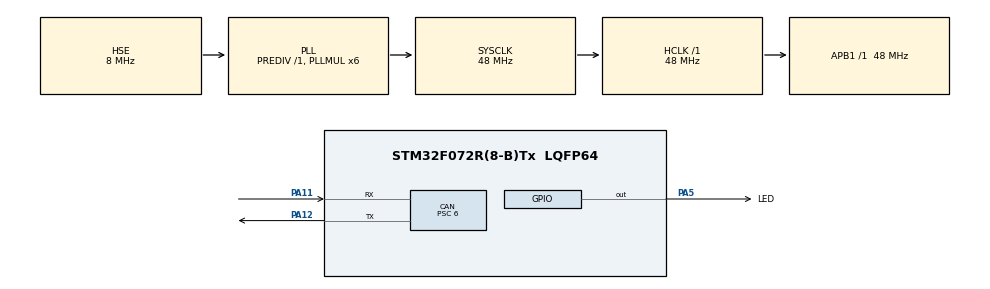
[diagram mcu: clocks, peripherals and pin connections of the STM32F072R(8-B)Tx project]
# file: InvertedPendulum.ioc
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CAN.ABOM=ENABLE
CAN.BS1=CAN_BS1_6TQ
CAN.CalculateBaudRate=1000000
CAN.CalculateTimeBit=1000
CAN.CalculateTimeQuantum=125.0
CAN.NART=DISABLE
CAN.Prescaler=6
Mcu.Family=STM32F0
Mcu.Name=STM32F072R(8-B)Tx
Mcu.Package=LQFP64
NVIC.CEC_CAN_IRQn=true\:0\:0\:false\:false\:true\:true\:true\:true
PA11.Mode=CAN_Activate
PA11.Signal=CAN_RX
PA12.Mode=CAN_Activate
PA12.Signal=CAN_TX
PA5.GPIO_Label=LED
PA5.Signal=GPIO_Output
PF0-OSC_IN.Mode=HSE-External-Clock-Source
PF0-OSC_IN.Signal=RCC_OSC_IN
ProjectManager.HeapSize=0x200
ProjectManager.StackSize=0x400
ProjectManager.TargetToolchain=CMake
RCC.AHBFreq_Value=48000000
RCC.APB1Freq_Value=48000000
RCC.APB1TimFreq_Value=48000000
RCC.HCLKFreq_Value=48000000
RCC.PLLMUL=RCC_PLL_MUL6
RCC.PLLSourceVirtual=RCC_PLLSOURCE_HSE
RCC.SYSCLKFreq_VALUE=48000000
RCC.SYSCLKSource=RCC_SYSCLKSOURCE_PLLCLK
board=NUCLEO-F072RB

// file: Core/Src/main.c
/* USER CODE BEGIN Header */
/**
  ******************************************************************************
  * @file           : main.c
  * @brief          : Main program body
  ******************************************************************************
  * @attention
  *
  * Copyright (c) 2026 STMicroelectronics.
  * All rights reserved.
  *
  * This software is licensed under terms that can be found in the LICENSE file
  * in the root directory of this software component.
  * If no LICENSE file comes with this software, it is provided AS-IS.
  *
  ******************************************************************************
  */
/* USER CODE END Header */
#include "main.h"

#include <string.h>

CAN_HandleTypeDef hcan;

/* USER CODE BEGIN PV */
uint32_t TxMailbox;
CAN_TxHeaderTypeDef TxHeader;
uint8_t TxData[8] = {0};

float motor_spin = 0.0f;

uint32_t TicksSinceChange = 0;

CAN_RxHeaderTypeDef RxHeaderFIFO0;
uint8_t RxDataFIFO0[8];

__IO uint32_t rx_heartbeat = 0;
__IO uint32_t rx_node = 0;
__IO uint32_t rx_command = 0;
/* USER CODE END PV */

void SystemClock_Config(void);
static void MX_GPIO_Init(void);
static void MX_CAN_Init(void);

int main(void)
{

  /* MCU Configuration--------------------------------------------------------*/

  /* Reset of all peripherals, Initializes the Flash interface and the Systick. */
  HAL_Init();

  /* Configure the system clock */
  SystemClock_Config();

  /* Initialize all configured peripherals */
  MX_GPIO_Init();
  MX_CAN_Init();
  /* USER CODE BEGIN 2 */
  TxHeader.StdId = (0x00 << 5) + 0x00d; // Node ID 0; Set_Input_Vel command
  TxHeader.IDE = CAN_ID_STD;
  TxHeader.RTR = CAN_RTR_DATA;
  TxHeader.DLC = 8;
  TxHeader.TransmitGlobalTime = DISABLE;
  /* USER CODE END 2 */

  /* Infinite loop */
  while (1)
  {

    if ((HAL_GetTick() - TicksSinceChange) > 2000)
    {
      TicksSinceChange = HAL_GetTick();

      motor_spin = (motor_spin == 0.0f) ? 1.0f : 0.0f;
      memset(TxData, 0, sizeof(TxData));
      memcpy(TxData, &motor_spin, sizeof(motor_spin));

      while (HAL_CAN_GetTxMailboxesFreeLevel(&hcan) == 0) {}

      if (HAL_CAN_AddTxMessage(&hcan, &TxHeader, TxData, &TxMailbox) != HAL_OK)
      {
        Error_Handler();
      }
    }
  }
}

void SystemClock_Config(void)
{
  RCC_OscInitTypeDef RCC_OscInitStruct = {0};
  RCC_ClkInitTypeDef RCC_ClkInitStruct = {0};

  /** Initializes the RCC Oscillators according to the specified parameters
  * in the RCC_OscInitTypeDef structure.
  */
  RCC_OscInitStruct.OscillatorType = RCC_OSCILLATORTYPE_HSE;
  RCC_OscInitStruct.HSEState = RCC_HSE_BYPASS;
  RCC_OscInitStruct.PLL.PLLState = RCC_PLL_ON;
  RCC_OscInitStruct.PLL.PLLSource = RCC_PLLSOURCE_HSE;
  RCC_OscInitStruct.PLL.PLLMUL = RCC_PLL_MUL6;
  RCC_OscInitStruct.PLL.PREDIV = RCC_PREDIV_DIV1;
  if (HAL_RCC_OscConfig(&RCC_OscInitStruct) != HAL_OK)
  {
    Error_Handler();
  }

  /** Initializes the CPU, AHB and APB buses clocks
  */
  RCC_ClkInitStruct.ClockType = RCC_CLOCKTYPE_HCLK|RCC_CLOCKTYPE_SYSCLK
                              |RCC_CLOCKTYPE_PCLK1;
  RCC_ClkInitStruct.SYSCLKSource = RCC_SYSCLKSOURCE_PLLCLK;
  RCC_ClkInitStruct.AHBCLKDivider = RCC_SYSCLK_DIV1;
  RCC_ClkInitStruct.APB1CLKDivider = RCC_HCLK_DIV1;

  if (HAL_RCC_ClockConfig(&RCC_ClkInitStruct, FLASH_LATENCY_1) != HAL_OK)
  {
    Error_Handler();
  }
}

static void MX_CAN_Init(void)
{

  /* USER CODE BEGIN CAN_Init 0 */
  CAN_FilterTypeDef sFilterConfig;
  /* USER CODE END CAN_Init 0 */

  hcan.Instance = CAN;
  hcan.Init.Prescaler = 6;
  hcan.Init.Mode = CAN_MODE_NORMAL;
  hcan.Init.SyncJumpWidth = CAN_SJW_1TQ;
  hcan.Init.TimeSeg1 = CAN_BS1_6TQ;
  hcan.Init.TimeSeg2 = CAN_BS2_1TQ;
  hcan.Init.TimeTriggeredMode = DISABLE;
  hcan.Init.AutoBusOff = ENABLE;
  hcan.Init.AutoWakeUp = DISABLE;
  hcan.Init.AutoRetransmission = DISABLE;
  hcan.Init.ReceiveFifoLocked = DISABLE;
  hcan.Init.TransmitFifoPriority = DISABLE;
  if (HAL_CAN_Init(&hcan) != HAL_OK)
  {
    Error_Handler();
  }
  /* USER CODE BEGIN CAN_Init 2 */
  sFilterConfig.FilterBank = 0;
  sFilterConfig.FilterMode = CAN_FILTERMODE_IDMASK;
  sFilterConfig.FilterScale = CAN_FILTERSCALE_32BIT;
  sFilterConfig.FilterIdHigh = 0x0000;
  sFilterConfig.FilterIdLow = 0x0000;
  sFilterConfig.FilterMaskIdHigh = 0x0000;
  sFilterConfig.FilterMaskIdLow = 0x0004;
  sFilterConfig.FilterFIFOAssignment = CAN_RX_FIFO0;
  sFilterConfig.FilterActivation = ENABLE;

  if (HAL_CAN_ConfigFilter(&hcan, &sFilterConfig) != HAL_OK)
  {
    Error_Handler();
  }

  if (HAL_CAN_Start(&hcan) != HAL_OK)
  {
    Error_Handler();
  }

  if (HAL_CAN_ActivateNotification(&hcan, CAN_IT_RX_FIFO0_MSG_PENDING) != HAL_OK)
  {
    Error_Handler();
  }
  /* USER CODE END CAN_Init 2 */

}

static void MX_GPIO_Init(void)
{
  GPIO_InitTypeDef GPIO_InitStruct = {0};

  /* GPIO Ports Clock Enable */
  __HAL_RCC_GPIOF_CLK_ENABLE();
  __HAL_RCC_GPIOA_CLK_ENABLE();

  /*Configure GPIO pin Output Level */
  HAL_GPIO_WritePin(LED_GPIO_Port, LED_Pin, GPIO_PIN_RESET);

  /*Configure GPIO pin : LED_Pin */
  GPIO_InitStruct.Pin = LED_Pin;
  GPIO_InitStruct.Mode = GPIO_MODE_OUTPUT_PP;
  GPIO_InitStruct.Pull = GPIO_NOPULL;
  GPIO_InitStruct.Speed = GPIO_SPEED_FREQ_LOW;
  HAL_GPIO_Init(LED_GPIO_Port, &GPIO_InitStruct);

}

/* USER CODE BEGIN 4 */
void HAL_CAN_RxFifo0MsgPendingCallback(CAN_HandleTypeDef* CanHandle)
{
  if (HAL_CAN_GetRxMessage(CanHandle, CAN_RX_FIFO0, &RxHeaderFIFO0, RxDataFIFO0) != HAL_OK)
  {
    Error_Handler();
  }
  else
  {
    rx_node = RxHeaderFIFO0.StdId >> 5;
    rx_command = RxHeaderFIFO0.StdId - (rx_node << 5);
    rx_heartbeat++;
  }
}
/* USER CODE END 4 */

void Error_Handler(void)
{
  /* USER CODE BEGIN Error_Handler_Debug */
  /* User can add his own implementation to report the HAL error return state */
  __disable_irq();
  while (1)
  {
    HAL_GPIO_TogglePin(LED_GPIO_Port, LED_Pin);

    for (__IO uint32_t i = 0; i < 0xFFFFF; i++);
  }
  /* USER CODE END Error_Handler_Debug */
}
